# R7FA2A2AD register map
Vendor: Renesas Electronics Corporation; Series: RA2A2; File version: 1.20.02
CPU: CM23 r1p0, little endian, MPU, no FPU, VTOR, 2 interrupt priority bits, 32 interrupts
Registers are 8-bit, read-write, reset 0x0 unless marked. A register's access mark holds for its fields unless they carry their own. Offsets are from the block's base; [hi:lo] are bit positions; 'fields as' and 'values as' point back to an identical list.

## SCI0 — Serial Communication Interface 0
Base 0x40070000
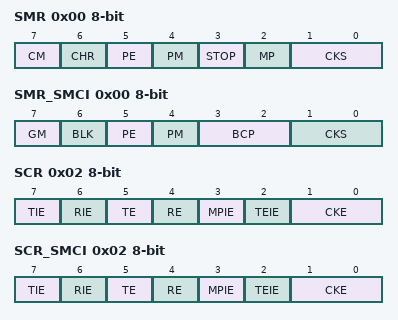
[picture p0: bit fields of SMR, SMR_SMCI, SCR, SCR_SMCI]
0x00 SMR — Serial Mode Register for Non,Smart Card Interface Mode (SCMR.SMIF = 0)
  [7] CM — Communication Mode
  [6] CHR — Character Length
  [5] PE — Parity Enable
  [4] PM — Parity Mode
  [3] STOP — Stop Bit Length
  [2] MP — Multi,Processor Mode
  [1:0] CKS — Clock Select
0x00 SMR_SMCI (alternate view of SMR) — Serial Mode Register for Smart Card Interface Mode (SCMR.SMIF = 1)
  [7] GM — GSM Mode
  [6] BLK — Block Transfer Mode
  [5] PE — Parity Enable
  [4] PM — Parity Mode
  [3:2] BCP — Base Clock Pulse
  [1:0] CKS — Clock Select
0x01 BRR reset 0xFF — Bit Rate Register
0x02 SCR — Serial Control Register for Non,Smart Card Interface Mode (SCMR.SMIF = 0)
  [7] TIE — Transmit Interrupt Enable
  [6] RIE — Receive Interrupt Enable
  [5] TE — Transmit Enable
  [4] RE — Receive Enable
  [3] MPIE — Multi,Processor Interrupt Enable
  [2] TEIE — Transmit End Interrupt Enable
  [1:0] CKE — Clock Enable
0x02 SCR_SMCI (alternate view of SCR) — Serial Control Register for Smart Card Interface Mode (SCMR.SMIF = 1)
  fields as SCR
0x03 TDR reset 0xFF — Transmit Data Register
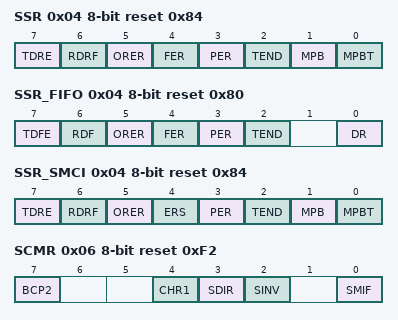
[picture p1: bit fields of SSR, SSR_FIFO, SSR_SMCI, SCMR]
0x04 SSR reset 0x84 — Serial Status Register for Non,Smart Card Interface and Non,FIFO Mode (SCMR.SMIF = 0, FCR.FM = 0)
  [7] TDRE — Transmit Data Empty Flag
  [6] RDRF — Receive Data Full Flag
  [5] ORER — Overrun Error Flag
  [4] FER — Framing Error Flag
  [3] PER — Parity Error Flag
  [2] TEND ro — Transmit End Flag
  [1] MPB ro — Multi,Processor
  [0] MPBT — Multi,Processor Bit Transfer
0x04 SSR_FIFO reset 0x80 (alternate view of SSR) — Serial Status Register for Non,Smart Card Interface and FIFO Mode (SCMR.SMIF = 0, FCR.FM = 1)
  [7] TDFE — Transmit FIFO Data Empty Flag
  [6] RDF — Receive FIFO Data Full Flag
  [5] ORER — Overrun Error Flag
  [4] FER — Framing Error Flag
  [3] PER — Parity Error Flag
  [2] TEND — Transmit End Flag
  [0] DR — Receive Data Ready Flag
0x04 SSR_SMCI reset 0x84 (alternate view of SSR) — Serial Status Register for Smart Card Interface Mode (SCMR.SMIF = 1)
  [7] TDRE — Transmit Data Empty Flag
  [6] RDRF — Receive Data Full Flag
  [5] ORER — Overrun Error Flag
  [4] ERS — Error Signal Status Flag
  [3] PER — Parity Error Flag
  [2] TEND ro — Transmit End Flag
  [1] MPB ro — Multi,Processor
  [0] MPBT — Multi,Processor Bit Transfer
0x05 RDR — Receive Data Register
0x06 SCMR reset 0xF2 — Smart Card Mode Register
  [7] BCP2 — Base Clock Pulse 2
  [4] CHR1 — Character Length 1
  [3] SDIR — Transmitted/Received Data Transfer Direction
  [2] SINV — Transmitted/Received Data Invert
  [0] SMIF — Smart Card Interface Mode Select
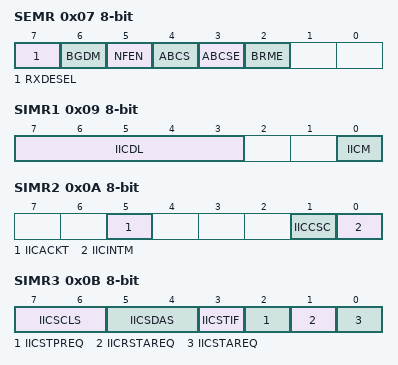
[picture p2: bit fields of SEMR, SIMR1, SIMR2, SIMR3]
0x07 SEMR — Serial Extended Mode Register
  [7] RXDESEL — Asynchronous Start Bit Edge Detection Select
  [6] BGDM — Baud Rate Generator Double,Speed Mode Select
  [5] NFEN — Digital Noise Filter Function Enable
  [4] ABCS — Asynchronous Mode Base Clock Select
  [3] ABCSE — Asynchronous Mode Extended Base Clock Select 1
  [2] BRME — Bit Rate Modulation Enable
0x08 SNFR — Noise Filter Setting Register
  [2:0] NFCS — Noise Filter Clock Select
0x09 SIMR1 — IIC Mode Register 1
  [7:3] IICDL — SDAn Delay Output Select
  [0] IICM — Simple IIC Mode Select
0x0A SIMR2 — IIC Mode Register 2
  [5] IICACKT — ACK Transmission Data
  [1] IICCSC — Clock Synchronization
  [0] IICINTM — IIC Interrupt Mode Select
0x0B SIMR3 — IIC Mode Register 3
  [7:6] IICSCLS — SCLn Output Select
  [5:4] IICSDAS — SDAn Output Select
  [3] IICSTIF — Issuing of Start, Restart, or Stop Condition Completed Flag
  [2] IICSTPREQ — Stop Condition Generation
  [1] IICRSTAREQ — Restart Condition Generation
  [0] IICSTAREQ — Start Condition Generation
0x0C SISR ro — IIC Status Register
  [0] IICACKR — ACK Reception Data Flag
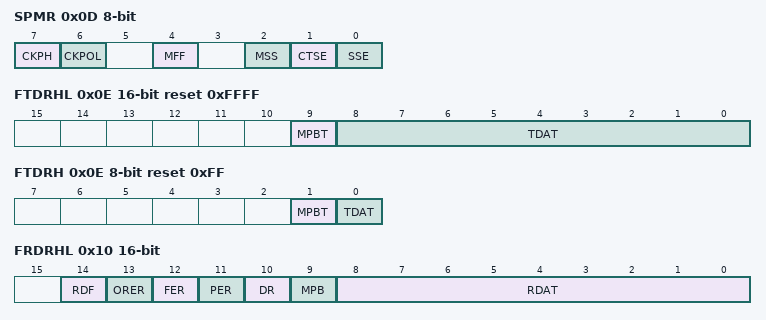
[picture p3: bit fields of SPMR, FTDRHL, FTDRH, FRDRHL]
0x0D SPMR — SPI Mode Register
  [7] CKPH — Clock Phase Select
  [6] CKPOL — Clock Polarity Select
  [4] MFF — Mode Fault Flag
  [2] MSS — Master Slave Select
  [1] CTSE — CTS Enable
  [0] SSE — SSn Pin Function Enable
0x0E FTDRHL 16-bit wo reset 0xFFFF — Transmit FIFO Data Register
  [9] MPBT — Multi,Processor Transfer Bit Flag
  [8:0] TDAT — Serial transmit data
0x0E TDRHL 16-bit reset 0xFFFF (alternate view of FTDRHL) — Transmit Data Register
  [8:0] TDAT — Serial Transmit Data
0x0E FTDRH wo reset 0xFF (alternate view of FTDRHL) — Transmit FIFO Data Register
  [1] MPBT — Multi,Processor Transfer Bit Flag
  [0] TDAT — Serial transmit data
0x0F FTDRL wo reset 0xFF (alternate view of FTDRHL) — Transmit FIFO Data Register
  [7:0] TDAT — Serial transmit data
0x10 FRDRHL 16-bit ro — Receive FIFO Data Register
  [14] RDF — Receive FIFO Data Full Flag
  [13] ORER — Overrun Error Flag
  [12] FER — Framing Error Flag
  [11] PER — Parity Error Flag
  [10] DR — Receive Data Ready Flag
  [9] MPB — Multi,Processor Bit Flag
  [8:0] RDAT — Serial receive data
0x10 RDRHL 16-bit ro (alternate view of FRDRHL) — Receive Data Register
  [8:0] RDAT — Serial Receive Data
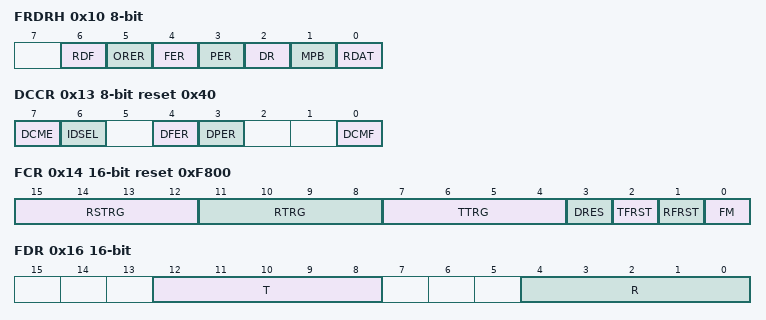
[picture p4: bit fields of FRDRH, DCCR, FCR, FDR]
0x10 FRDRH ro (alternate view of FRDRHL) — Receive FIFO Data Register
  [6] RDF — Receive FIFO Data Full Flag
  [5] ORER — Overrun Error Flag
  [4] FER — Framing Error Flag
  [3] PER — Parity Error Flag
  [2] DR — Receive Data Ready Flag
  [1] MPB — Multi,Processor Bit Flag
  [0] RDAT — Serial receive data
0x11 FRDRL ro (alternate view of FRDRHL) — Receive FIFO Data Register
  [7:0] RDAT — Serial receive data
0x12 MDDR reset 0xFF — Modulation Duty Register
0x13 DCCR reset 0x40 — Data Compare Match Control Register
  [7] DCME — Data Compare Match Enable
  [6] IDSEL — ID Frame Select
  [4] DFER — Data Compare Match Framing Error Flag
  [3] DPER — Data Compare Match Parity Error Flag
  [0] DCMF — Data Compare Match Flag
0x14 FCR 16-bit reset 0xF800 — FIFO Control Register
  [15:12] RSTRG — RTS Output Active Trigger Number Select
  [11:8] RTRG — Receive FIFO Data Trigger Number
  [7:4] TTRG — Transmit FIFO Data Trigger Number
  [3] DRES — Receive Data Ready Error Select
  [2] TFRST — Transmit FIFO Data Register Reset
  [1] RFRST — Receive FIFO Data Register Reset
  [0] FM — FIFO Mode Select
0x16 FDR 16-bit ro — FIFO Data Count Register
  [12:8] T — Transmit FIFO Data Count
  [4:0] R — Receive FIFO Data Count
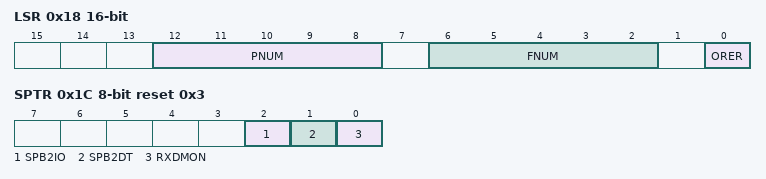
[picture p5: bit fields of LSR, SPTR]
0x18 LSR 16-bit ro — Line Status Register
  [12:8] PNUM — Parity Error Count
  [6:2] FNUM — Framing Error Count
  [0] ORER — Overrun Error Flag
0x1A CDR 16-bit — Compare Match Data Register
  [8:0] CMPD — Compare Match Data
0x1C SPTR reset 0x3 — Serial Port Register
  [2] SPB2IO — Serial Port Break I/O
  [1] SPB2DT — Serial Port Break Data Select
  [0] RXDMON ro — Serial Input Data Monitor

## SCI1 — Serial Communication Interface 1
Base 0x40070020
Same registers: SCI2 0x40070040, SCI3 0x40070060, SCI9 0x40070120
Registers as SCI0, without SSR_FIFO, FTDRHL, FTDRH, FTDRL, FRDRHL, FRDRH, FRDRL, FCR, FDR, LSR.
